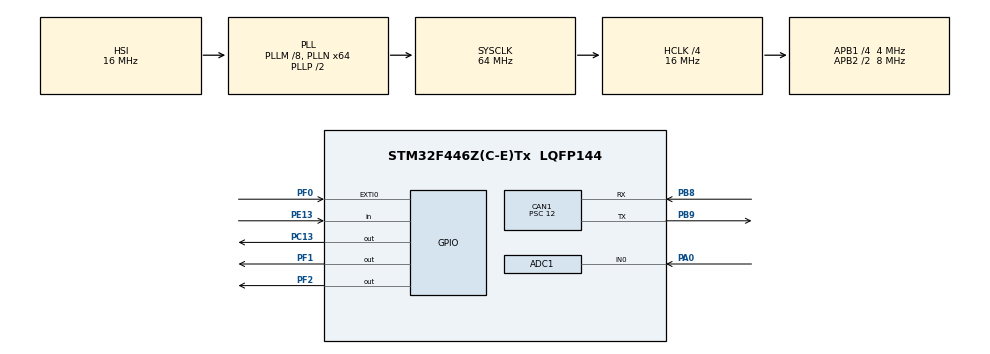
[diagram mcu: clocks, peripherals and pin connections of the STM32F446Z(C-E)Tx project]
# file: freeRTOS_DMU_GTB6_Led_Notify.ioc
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ADC1.Channel-0\#ChannelRegularConversion=ADC_CHANNEL_0
ADC1.NbrOfConversionFlag=1
ADC1.Rank-0\#ChannelRegularConversion=1
ADC1.SamplingTime-0\#ChannelRegularConversion=ADC_SAMPLETIME_3CYCLES
ADC1.master=1
CAN1.BS1=CAN_BS1_11TQ
CAN1.BS2=CAN_BS2_2TQ
CAN1.CalculateBaudRate=23809
CAN1.CalculateTimeBit=42000
CAN1.CalculateTimeQuantum=3000.0
CAN1.Prescaler=12
FREERTOS.Tasks01=myTask01,-1,128,StartDefaultTask,Default,NULL,Dynamic,NULL,NULL;myTask02,-1,128,StartTask02,Default,NULL,Dynamic,NULL,NULL
FREERTOS.configUSE_NEWLIB_REENTRANT=1
Mcu.Family=STM32F4
Mcu.Name=STM32F446Z(C-E)Tx
Mcu.Package=LQFP144
NVIC.CAN1_RX0_IRQn=true\:5\:0\:false\:false\:true\:true\:true\:true\:true
NVIC.PriorityGroup=NVIC_PRIORITYGROUP_4
PA0-WKUP.Signal=ADCx_IN0
PB8.Mode=CAN_Activate
PB8.Signal=CAN1_RX
PB9.Mode=CAN_Activate
PB9.Signal=CAN1_TX
PC13.Signal=GPIO_Output
PE13.Signal=GPIO_Input
PF0.Signal=GPXTI0
PF1.Signal=GPIO_Output
PF2.Signal=GPIO_Output
PH0-OSC_IN.Mode=HSE-External-Oscillator
PH0-OSC_IN.Signal=RCC_OSC_IN
PH1-OSC_OUT.Mode=HSE-External-Oscillator
PH1-OSC_OUT.Signal=RCC_OSC_OUT
ProjectManager.HeapSize=0x200
ProjectManager.StackSize=0x400
ProjectManager.TargetToolchain=STM32CubeIDE
RCC.AHBCLKDivider=RCC_SYSCLK_DIV4
RCC.AHBFreq_Value=16000000
RCC.APB1CLKDivider=RCC_HCLK_DIV4
RCC.APB1Freq_Value=4000000
RCC.APB1TimFreq_Value=8000000
RCC.APB2CLKDivider=RCC_HCLK_DIV2
RCC.APB2Freq_Value=8000000
RCC.APB2TimFreq_Value=16000000
RCC.CortexFreq_Value=16000000
RCC.HCLKFreq_Value=16000000
RCC.HSE_VALUE=8000000
RCC.PLLM=8
RCC.PLLN=64
RCC.SYSCLKFreq_VALUE=64000000
RCC.SYSCLKSource=RCC_SYSCLKSOURCE_PLLCLK
RCC.USBFreq_Value=64000000
RCC.VCOOutputFreq_Value=128000000
SH.ADCx_IN0.0=ADC1_IN0,IN0
VP_FREERTOS_VS_CMSIS_V1.Mode=CMSIS_V1
board=custom

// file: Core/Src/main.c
/* USER CODE BEGIN Header */
/**
  ******************************************************************************
  * @file           : main.c
  * @brief          : Main program body
  ******************************************************************************
  * @attention
  *
  * Copyright (c) 2024 STMicroelectronics.
  * All rights reserved.
  *
  * This software is licensed under terms that can be found in the LICENSE file
  * in the root directory of this software component.
  * If no LICENSE file comes with this software, it is provided AS-IS.
  *
  ******************************************************************************
  */
/* USER CODE END Header */
#include "main.h"
#include "cmsis_os.h" // os dosyaları için

/* USER CODE BEGIN Includes */
#include "task.h" // task dosyaları için
/* USER CODE END Includes */

ADC_HandleTypeDef hadc1;

CAN_HandleTypeDef hcan1;

osThreadId myTask01Handle;
osThreadId myTask02Handle;
/* USER CODE BEGIN PV */
//TaskHandle_t myTask01Handle;
//TaskHandle_t myTask02Handle;

/* USER CODE END PV */

void SystemClock_Config(void);
static void MX_GPIO_Init(void);
static void MX_ADC1_Init(void);
static void MX_CAN1_Init(void);
void StartDefaultTask(void const * argument);
void StartTask02(void const * argument);

void vApplicationIdleHook()
{
	__WFI();
}

/* USER CODE BEGIN 0 */

uint32_t dmu_value;
uint32_t digital_output;
/* USER CODE END 0 */

int main(void)
{

  /* MCU Configuration--------------------------------------------------------*/

  /* Reset of all peripherals, Initializes the Flash interface and the Systick. */
  HAL_Init();

  /* Configure the system clock */
  SystemClock_Config();

  /* USER CODE BEGIN SysInit */
  SystemCoreClockUpdate();
  /* USER CODE END SysInit */

  /* Initialize all configured peripherals */
  MX_GPIO_Init();
  MX_ADC1_Init();
  MX_CAN1_Init();

  /* Create the thread(s) */
  /* definition and creation of myTask01 */
//  osThreadDef(myTask01, StartDefaultTask, osPriorityBelowNormal, 0, 128);
//  myTask01Handle = osThreadCreate(osThread(myTask01), NULL);

//     xTaskCreate(StartDefaultTask," DMU OKUMA ",128, NULL, 4, &myTask01_attributes); * stack size parametresi 128

  /* definition and creation of myTask02 */
//  osThreadDef(myTask02, StartTask02, osPriorityBelowNormal, 0, 128);
//  myTask02Handle = osThreadCreate(osThread(myTask02), NULL);

  /* USER CODE BEGIN RTOS_THREADS */
  /* add threads, ... */

  xTaskCreate(StartDefaultTask," DMU OKUMA ",configMINIMAL_STACK_SIZE, NULL, 2, &myTask01Handle);
  xTaskCreate(StartTask02," Led yakma ", configMINIMAL_STACK_SIZE, NULL, 2, &myTask02Handle);

  /* USER CODE END RTOS_THREADS */

  /* Start scheduler */
//  osKernelStart();
  vTaskStartScheduler();
  /* We should never get here as control is now taken by the scheduler */

  /* Infinite loop */
  while (1)
  {

  }
}

void SystemClock_Config(void)
{
  RCC_OscInitTypeDef RCC_OscInitStruct = {0};
  RCC_ClkInitTypeDef RCC_ClkInitStruct = {0};

  /** Configure the main internal regulator output voltage
  */
  __HAL_RCC_PWR_CLK_ENABLE();
  __HAL_PWR_VOLTAGESCALING_CONFIG(PWR_REGULATOR_VOLTAGE_SCALE3);

  /** Initializes the RCC Oscillators according to the specified parameters
  * in the RCC_OscInitTypeDef structure.
  */
  RCC_OscInitStruct.OscillatorType = RCC_OSCILLATORTYPE_HSI;
  RCC_OscInitStruct.HSIState = RCC_HSI_ON;
  RCC_OscInitStruct.HSICalibrationValue = RCC_HSICALIBRATION_DEFAULT;
  RCC_OscInitStruct.PLL.PLLState = RCC_PLL_ON;
  RCC_OscInitStruct.PLL.PLLSource = RCC_PLLSOURCE_HSI;
  RCC_OscInitStruct.PLL.PLLM = 8;
  RCC_OscInitStruct.PLL.PLLN = 64;
  RCC_OscInitStruct.PLL.PLLP = RCC_PLLP_DIV2;
  RCC_OscInitStruct.PLL.PLLQ = 2;
  RCC_OscInitStruct.PLL.PLLR = 2;
  if (HAL_RCC_OscConfig(&RCC_OscInitStruct) != HAL_OK)
  {
    Error_Handler();
  }

  /** Initializes the CPU, AHB and APB buses clocks
  */
  RCC_ClkInitStruct.ClockType = RCC_CLOCKTYPE_HCLK|RCC_CLOCKTYPE_SYSCLK
                              |RCC_CLOCKTYPE_PCLK1|RCC_CLOCKTYPE_PCLK2;
  RCC_ClkInitStruct.SYSCLKSource = RCC_SYSCLKSOURCE_PLLCLK;
  RCC_ClkInitStruct.AHBCLKDivider = RCC_SYSCLK_DIV4;
  RCC_ClkInitStruct.APB1CLKDivider = RCC_HCLK_DIV4;
  RCC_ClkInitStruct.APB2CLKDivider = RCC_HCLK_DIV2;

  if (HAL_RCC_ClockConfig(&RCC_ClkInitStruct, FLASH_LATENCY_0) != HAL_OK)
  {
    Error_Handler();
  }
}

static void MX_ADC1_Init(void)
{

  ADC_ChannelConfTypeDef sConfig = {0};

  /** Configure the global features of the ADC (Clock, Resolution, Data Alignment and number of conversion)
  */
  hadc1.Instance = ADC1;
  hadc1.Init.ClockPrescaler = ADC_CLOCK_SYNC_PCLK_DIV2;
  hadc1.Init.Resolution = ADC_RESOLUTION_12B;
  hadc1.Init.ScanConvMode = DISABLE;
  hadc1.Init.ContinuousConvMode = DISABLE;
  hadc1.Init.DiscontinuousConvMode = DISABLE;
  hadc1.Init.ExternalTrigConvEdge = ADC_EXTERNALTRIGCONVEDGE_NONE;
  hadc1.Init.ExternalTrigConv = ADC_SOFTWARE_START;
  hadc1.Init.DataAlign = ADC_DATAALIGN_RIGHT;
  hadc1.Init.NbrOfConversion = 1;
  hadc1.Init.DMAContinuousRequests = DISABLE;
  hadc1.Init.EOCSelection = ADC_EOC_SINGLE_CONV;
  if (HAL_ADC_Init(&hadc1) != HAL_OK)
  {
    Error_Handler();
  }

  /** Configure for the selected ADC regular channel its corresponding rank in the sequencer and its sample time.
  */
  sConfig.Channel = ADC_CHANNEL_0;
  sConfig.Rank = 1;
  sConfig.SamplingTime = ADC_SAMPLETIME_3CYCLES;
  if (HAL_ADC_ConfigChannel(&hadc1, &sConfig) != HAL_OK)
  {
    Error_Handler();
  }

}

static void MX_CAN1_Init(void)
{

  hcan1.Instance = CAN1;
  hcan1.Init.Prescaler = 12;
  hcan1.Init.Mode = CAN_MODE_NORMAL;
  hcan1.Init.SyncJumpWidth = CAN_SJW_1TQ;
  hcan1.Init.TimeSeg1 = CAN_BS1_11TQ;
  hcan1.Init.TimeSeg2 = CAN_BS2_2TQ;
  hcan1.Init.TimeTriggeredMode = DISABLE;
  hcan1.Init.AutoBusOff = DISABLE;
  hcan1.Init.AutoWakeUp = DISABLE;
  hcan1.Init.AutoRetransmission = DISABLE;
  hcan1.Init.ReceiveFifoLocked = DISABLE;
  hcan1.Init.TransmitFifoPriority = DISABLE;
  if (HAL_CAN_Init(&hcan1) != HAL_OK)
  {
    Error_Handler();
  }

}

static void MX_GPIO_Init(void)
{
  GPIO_InitTypeDef GPIO_InitStruct = {0};

  /* GPIO Ports Clock Enable */
  __HAL_RCC_GPIOC_CLK_ENABLE();
  __HAL_RCC_GPIOF_CLK_ENABLE();
  __HAL_RCC_GPIOH_CLK_ENABLE();
  __HAL_RCC_GPIOA_CLK_ENABLE();
  __HAL_RCC_GPIOE_CLK_ENABLE();
  __HAL_RCC_GPIOB_CLK_ENABLE();

  /*Configure GPIO pin Output Level */
  HAL_GPIO_WritePin(GPIOC, GPIO_PIN_13, GPIO_PIN_RESET);

  /*Configure GPIO pin Output Level */
  HAL_GPIO_WritePin(GPIOF, GPIO_PIN_1|GPIO_PIN_2, GPIO_PIN_RESET);

  /*Configure GPIO pin : PC13 */
  GPIO_InitStruct.Pin = GPIO_PIN_13;
  GPIO_InitStruct.Mode = GPIO_MODE_OUTPUT_PP;
  GPIO_InitStruct.Pull = GPIO_NOPULL;
  GPIO_InitStruct.Speed = GPIO_SPEED_FREQ_LOW;
  HAL_GPIO_Init(GPIOC, &GPIO_InitStruct);

  /*Configure GPIO pin : PF0 */
  GPIO_InitStruct.Pin = GPIO_PIN_0;
  GPIO_InitStruct.Mode = GPIO_MODE_IT_RISING;
  GPIO_InitStruct.Pull = GPIO_NOPULL;
  HAL_GPIO_Init(GPIOF, &GPIO_InitStruct);

  /*Configure GPIO pins : PF1 PF2 */
  GPIO_InitStruct.Pin = GPIO_PIN_1|GPIO_PIN_2;
  GPIO_InitStruct.Mode = GPIO_MODE_OUTPUT_PP;
  GPIO_InitStruct.Pull = GPIO_NOPULL;
  GPIO_InitStruct.Speed = GPIO_SPEED_FREQ_LOW;
  HAL_GPIO_Init(GPIOF, &GPIO_InitStruct);

  /*Configure GPIO pin : PE13 */
  GPIO_InitStruct.Pin = GPIO_PIN_13;
  GPIO_InitStruct.Mode = GPIO_MODE_INPUT;
  GPIO_InitStruct.Pull = GPIO_NOPULL;
  HAL_GPIO_Init(GPIOE, &GPIO_InitStruct);

}

void StartDefaultTask(void const * argument)
{
  /* USER CODE BEGIN 5 */
  /* Infinite loop */
  for(;;)
  {
	  HAL_GPIO_WritePin(GPIOA, GPIO_Pin_0, GPIO_PIN_SET);
	  HAL_GPIO_WritePin(GPIOA, GPIO_PIN_0, GPIO_PIN_RESET);
	  vTaskDelay(pdMS_TO_TICKS(1000));
  }
  /* USER CODE END 5 */
}

void StartTask02(void const * argument)
{
  /* USER CODE BEGIN StartTask02 */
	uint32_t pulNotificationValue = 0;
  /* Infinite loop */
  for(;;)
  {
	  HAL_GPIO_WritePin(GPIOC, GPIO_Pin_13, GPIO_PIN_SET);
	  HAL_GPIO_WritePin(GPIOC, GPIO_PIN_13, GPIO_PIN_RESET);
	  vTaskDelay(pdMS_TO_TICKS(1000));

  }
  /* USER CODE END StartTask02 */
}

void Error_Handler(void)
{
  __disable_irq();
  while (1)
  {
  }
}
